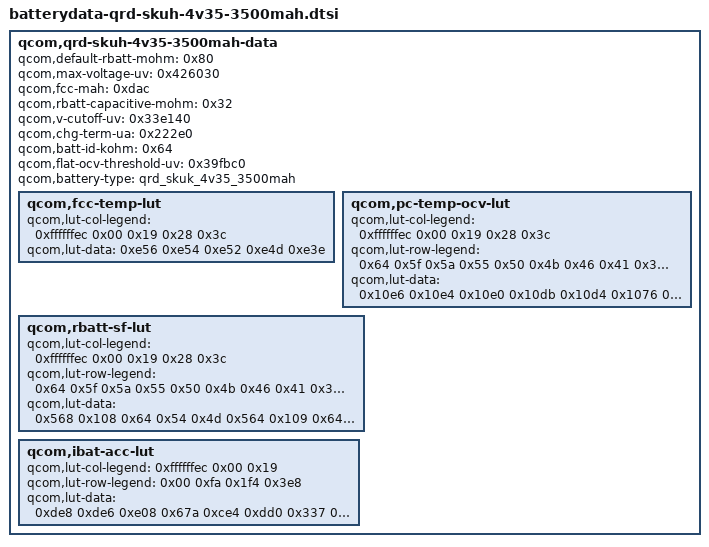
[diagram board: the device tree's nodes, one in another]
qcom,qrd-skuh-4v35-3500mah-data {
	qcom,default-rbatt-mohm = <0x80>;
	qcom,max-voltage-uv = <0x426030>;
	qcom,fcc-mah = <0xdac>;
	qcom,rbatt-capacitive-mohm = <0x32>;
	qcom,v-cutoff-uv = <0x33e140>;
	qcom,chg-term-ua = <0x222e0>;
	qcom,batt-id-kohm = <0x64>;
	qcom,flat-ocv-threshold-uv = <0x39fbc0>;
	qcom,battery-type = "qrd_skuk_4v35_3500mah";

	qcom,fcc-temp-lut {
		qcom,lut-col-legend = <0xffffffec 0x00 0x19 0x28 0x3c>;
		qcom,lut-data = <0xe56 0xe54 0xe52 0xe4d 0xe3e>;
	};

	qcom,pc-temp-ocv-lut {
		qcom,lut-col-legend = <0xffffffec 0x00 0x19 0x28 0x3c>;
		qcom,lut-row-legend = <0x64 0x5f 0x5a 0x55 0x50 0x4b 0x46 0x41 0x3c 0x37 0x32 0x2d 0x28 0x23 0x1e 0x19 0x14 0x10 0x0d 0x0b 0x0a 0x09 0x08 0x07 0x06 0x05 0x04 0x03 0x02 0x01 0x00>;
		qcom,lut-data = <0x10e6 0x10e4 0x10e0 0x10db 0x10d4 0x1076 0x108e 0x1095 0x1094 0x108e 0x1024 0x104c 0x1058 0x1057 0x1052 0xfe2 0x1012 0x101e 0x101e 0x101a 0xf94 0xfdb 0xfe8 0xfe7 0xfe4 0xf5c 0xf9e 0xfb4 0xfb4 0xfb0 0xf32 0xf69 0xf86 0xf86 0xf84 0xf0b 0xf3f 0xf5e 0xf5e 0xf5a 0xeee 0xf18 0xf30 0xf32 0xf30 0xeda 0xef8 0xf02 0xf04 0xf02 0xeca 0xede 0xee4 0xee6 0xee4 0xeba 0xeca 0xed0 0xed0 0xece 0xea8 0xebe 0xec0 0xec0 0xebe 0xe96 0xeb4 0xeb8 0xeb6 0xeb2 0xe7e 0xea7 0xeb0 0xeac 0xea4 0xe62 0xe94 0xea3 0xe9d 0xe90 0xe42 0xe76 0xe8c 0xe86 0xe79 0xe20 0xe52 0xe6a 0xe66 0xe5c 0xe05 0xe30 0xe48 0xe46 0xe3e 0xdea 0xe14 0xe32 0xe33 0xe2d 0xddc 0xe06 0xe28 0xe2c 0xe27 0xdcc 0xdf7 0xe1b 0xe22 0xe1f 0xdba 0xdea 0xe0c 0xe16 0xe14 0xda7 0xddc 0xdfa 0xe04 0xe04 0xd92 0xdcc 0xde8 0xdf1 0xdf1 0xd7a 0xdb8 0xdd3 0xdd9 0xdd8 0xd5e 0xd98 0xdaf 0xdb2 0xdaf 0xd39 0xd68 0xd75 0xd76 0xd71 0xd04 0xd23 0xd2a 0xd2c 0xd27 0xcaf 0xcc0 0xcc3 0xcc6 0xcc5 0xc1c 0xc1c 0xc1c 0xc1c 0xc28>;
	};

	qcom,rbatt-sf-lut {
		qcom,lut-col-legend = <0xffffffec 0x00 0x19 0x28 0x3c>;
		qcom,lut-row-legend = <0x64 0x5f 0x5a 0x55 0x50 0x4b 0x46 0x41 0x3c 0x37 0x32 0x2d 0x28 0x23 0x1e 0x19 0x14 0x10 0x0d 0x0b 0x0a 0x09 0x08 0x07 0x06 0x05 0x04 0x03 0x02 0x01 0x00>;
		qcom,lut-data = <0x568 0x108 0x64 0x54 0x4d 0x564 0x109 0x64 0x54 0x4d 0x4fa 0x112 0x67 0x54 0x4d 0x4b7 0x119 0x6a 0x56 0x4e 0x472 0x11f 0x6d 0x59 0x50 0x458 0x119 0x72 0x5b 0x50 0x458 0x109 0x78 0x5e 0x53 0x45c 0x103 0x80 0x64 0x56 0x46c 0x100 0x7b 0x64 0x58 0x48f 0xff 0x67 0x58 0x50 0x4c1 0xff 0x62 0x54 0x4d 0x4fd 0x106 0x64 0x54 0x4d 0x542 0x115 0x66 0x56 0x4f 0x59a 0x12b 0x69 0x58 0x51 0x601 0x150 0x70 0x59 0x50 0x6c8 0x184 0x74 0x5b 0x4f 0x863 0x1ca 0x7a 0x5b 0x50 0xa80 0x20b 0x7e 0x5e 0x50 0xc3a 0x23c 0x86 0x5f 0x51 0xf94 0x26c 0x93 0x64 0x53 0x1201 0x28d 0x9b 0x67 0x56 0x152e 0x2b5 0xa3 0x6d 0x58 0x197d 0x2e9 0xa6 0x6f 0x59 0x1f8c 0x330 0xab 0x70 0x59 0x283c 0x393 0xb1 0x70 0x59 0x34a7 0x431 0xb5 0x6f 0x58 0x46f1 0x570 0xb5 0x6d 0x55 0x6110 0x78e 0xbc 0x6e 0x56 0x8578 0xaca 0xcb 0x72 0x59 0xb2a0 0xf61 0xe7 0x7c 0x5c 0xbd0a 0x1a59 0x1af 0xf8 0xb8>;
	};

	qcom,ibat-acc-lut {
		qcom,lut-col-legend = <0xffffffec 0x00 0x19>;
		qcom,lut-row-legend = <0x00 0xfa 0x1f4 0x3e8>;
		qcom,lut-data = <0xde8 0xde6 0xe08 0x67a 0xce4 0xdd0 0x337 0xbb4 0xda8 0x2d 0x900 0xd06>;
	};
};
